# MCXN947_cm33_core0 register map
Vendor: nxp.com; File version: 1.0
CPU: CM33 r2p0, little endian, MPU, FPU, VTOR, 3 interrupt priority bits
Registers are 32-bit, read-write, reset 0x0 unless marked. A register's access mark holds for its fields unless they carry their own. Offsets are from the block's base; [hi:lo] are bit positions; {n}, {i} and the like mark numbered series.

## OTPC0 — OTPC
Base 0x400C9000
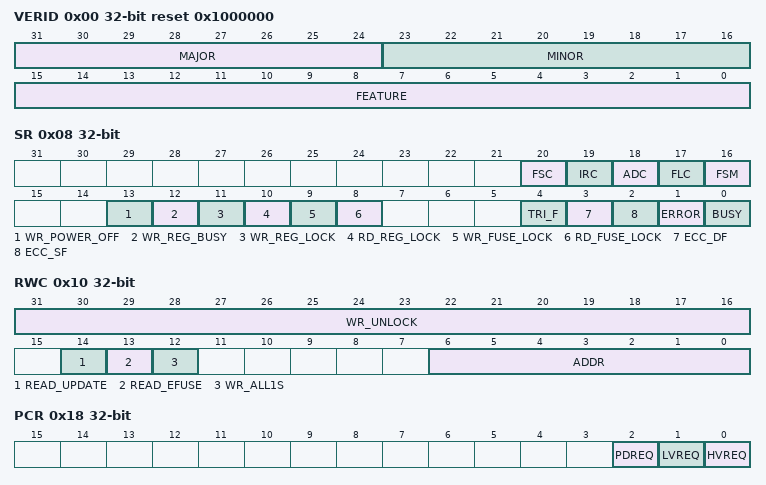
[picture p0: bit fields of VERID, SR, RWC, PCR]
0x00 VERID ro reset 0x1000000 — Version ID
  [31:24] MAJOR — Major Version Number
  [23:16] MINOR — Minor Version Number
  [15:0] FEATURE — Feature Specification Number
    0=STANDARD (Standard feature set)
0x04 PARAM ro reset 0x40 — Parameters
  [15:0] NUM_FUSE — Number of fuse bytes
0x08 SR — Status
  [20] FSC write-1-clears — Fuse and shadow register compare error
    0=NO_ERROR; 1=ERROR
  [19] IRC write-1-clears — Inverted register compare error
    0=NO_ERROR; 1=ERROR
  [18] ADC write-1-clears — Address and data compare error
    0=NO_ERROR; 1=ERROR
  [17] FLC write-1-clears — Fuse load counter error
    0=NO_ERROR; 1=ERROR
  [16] FSM write-1-clears — Finite-state machine error
    0=NO_ERROR; 1=ERROR
  [13] WR_POWER_OFF ro — Write when power off error
    0=NO_ERROR; 1=ERROR
  [12] WR_REG_BUSY ro — Write register when busy error
    0=NO_ERROR; 1=ERROR
  [11] WR_REG_LOCK ro — Write register lock error
    0=NO_ERROR; 1=ERROR
  [10] RD_REG_LOCK ro — Read register lock error
    0=NO_ERROR; 1=ERROR
  [9] WR_FUSE_LOCK ro — Write fuse lock error
    0=NO_ERROR; 1=ERROR
  [8] RD_FUSE_LOCK ro — Read fuse lock error
    0=NO_ERROR; 1=ERROR
  [4] TRI_F write-1-clears — Triple voting fault
    0=NO_FAULT; 1=FAULT
  [3] ECC_DF write-1-clears — ECC double fault
    0=NO_FAULT; 1=FAULT
  [2] ECC_SF write-1-clears — ECC single fault
    0=NO_FAULT; 1=FAULT
  [1] ERROR write-1-clears — Error flag
    0=NO_ERROR; 1=ERROR
  [0] BUSY ro — Busy status
    0=NOT_BUSY (Not busy (transaction complete)); 1=BUSY
0x10 RWC — Read and Write Control
  [31:16] WR_UNLOCK — Write Unlock
  [14] READ_UPDATE
    0=NO_UPDATE (Shadow register does not update); 1=UPDATE (Shadow register updates)
  [13] READ_EFUSE
    0=PROGRAM (Starts program operation when the WR_UNLOCK value is 0x9527; otherwise, takes no action.); 1=READ (Starts read operation)
  [12] WR_ALL1S — Write all 1s
    0=USE_WDATA (Uses the WDATA value); 1=USE_ALL1S (Writes all 1s)
  [6:0] ADDR — EFUSE address
0x14 RLC — Reload Control
  [0] RELOAD_SHADOWS — Reload shadow registers
    0=NO_ACTION (No action (when writing) or reload complete (when reading)); 1=RELOAD
0x18 PCR — Power Control
  [2] PDREQ — Power down request
    0=NO_ACTION (PD pin is set to low when OTPC is in idle state. It means EFUSE hardmacro is in standby mode. Idle state means OTPC is not in read and program modes.); 1=POWER_DN (PD pin is set to high when OTPC is in idle state. It means EFUSE hardmacro is in power down mode.)
  [1] LVREQ — Weak switch request
    0=TURN_OFF; 1=TURN_ON
  [0] HVREQ — Strong switch request
    0=TURN_OFF; 1=TURN_ON
0x20 WDATA — Write Data
  [31:0] DAT — Write data
0x24 RDATA ro — Read Data
  [31:0] DAT — Read data
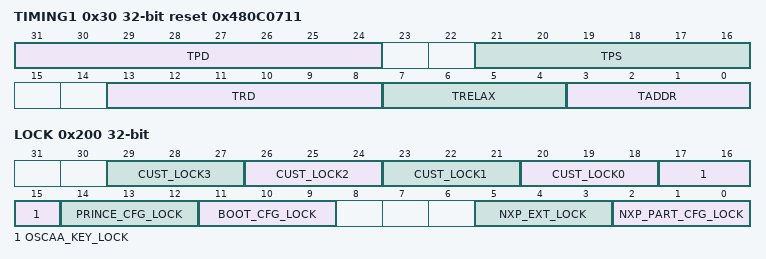
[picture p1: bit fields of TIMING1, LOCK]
0x30 TIMING1 reset 0x480C0711
  [31:24] TPD — PD to CSB setup time between power down signal deassertion and chip select signal assertion
  [21:16] TPS — PS to CSB setup and hold time between power switch and chip select assertion
  [13:8] TRD — Read strobe pulse width time
  [7:4] TRELAX — CSB, PGENB and LOAD to STROBE setup and hold time
  [3:0] TADDR — Address to STROBE setup and hold time
0x34 TIMING2 reset 0x600
  [11:0] TPGM — Typical program strobe pulse width time
0x200 LOCK
  [3n+20:3n+18] CUST_LOCK{n} ro (n=0..3)
  [17:15] OSCAA_KEY_LOCK ro
  [14:12] PRINCE_CFG_LOCK ro — Prince Config Lock
  [11:9] BOOT_CFG_LOCK ro — Boot config Lock
  [5:3] NXP_EXT_LOCK ro
  [2:0] NXP_PART_CFG_LOCK ro — NXP Part Config Lock
0x204 SECURE ro reset not defined
  [31:0] DAT — Data
0x208 SECURE_INV ro reset not defined — Inverted Secure
  [31:0] DAT — Data
0x20C DBG_KEY ro — Debug and Key
  [31:0] DAT — Data
0x210 MISC_CFG — MISC Config
  [31:0] DAT — Data
0x214 PHANTOM_CFG — PHANTOM Config
  [31:0] DAT — Data
0x218 FLEX_CFG0 — Flexible Config 0
  [31:0] DAT — Data
0x21C FLEX_CFG1 — Flexible Config 1
  [31:0] DAT — Data
